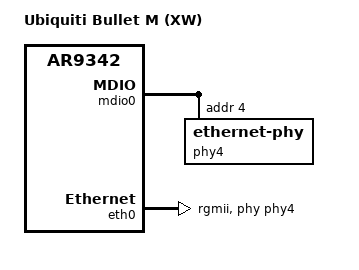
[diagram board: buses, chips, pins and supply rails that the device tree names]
// SPDX-License-Identifier: GPL-2.0-or-later OR MIT
/dts-v1/;

#include "ar9342_ubnt_xw.dtsi"

/ {
	compatible = "ubnt,bullet-m-xw", "ubnt,xw", "qca,ar9342";
	model = "Ubiquiti Bullet M (XW)";
};

&mdio0 {
	status = "okay";

	phy-mask = <4>;
	phy4: ethernet-phy@4 {
		phy-mode = "rgmii";
		reg = <4>;
	};
};

&eth0 {
	status = "okay";

	phy-mode = "rgmii";
	phy-handle = <&phy4>;

	gmac-config {
		device = <&gmac>;
		rxd-delay = <3>;
		rxdv-delay = <3>;
	};
};
